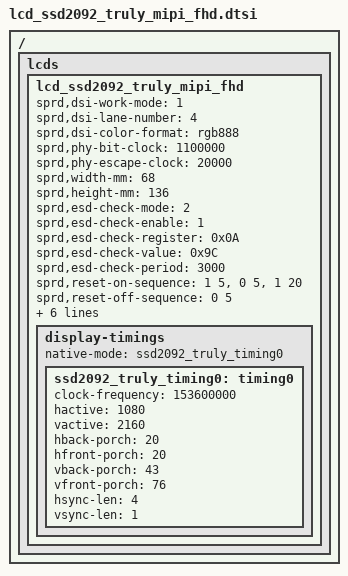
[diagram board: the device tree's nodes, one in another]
// SPDX-License-Identifier: GPL-2.0-only
/*
 * Unisoc SSD2092 Truly LCD config DTS file
 *
 * Copyright (C) 2021, Unisoc Inc.
 */
/ {
	fragment {
		target-path = "/";
		__overlay__ {
			lcds {
				lcd_ssd2092_truly_mipi_fhd: lcd_ssd2092_truly_mipi_fhd {

					sprd,dsi-work-mode = <1>; /* video burst mode*/
					sprd,dsi-lane-number = <4>;
					sprd,dsi-color-format = "rgb888";

					sprd,phy-bit-clock = <1100000>;  /* kbps */
					sprd,phy-escape-clock = <20000>; /* kHz */

					sprd,width-mm = <68>;
					sprd,height-mm = <136>;

					sprd,esd-check-mode = <2>;
					sprd,esd-check-enable = <1>;
					sprd,esd-check-register = <0x0A>;
					sprd,esd-check-value = <0x9C>;
					sprd,esd-check-period = <3000>;

					sprd,reset-on-sequence = <1 5>, <0 5>, <1 20>;
					sprd,reset-off-sequence = <0 5>;

					sprd,initial-command = [
						29 00 00 03 B5 00 00
						29 00 00 03 B3 03 96
						29 00 00 03 B4 21 FF
						29 00 00 03 E1 00 00
						29 00 00 04 E1 03 00 10
						29 00 00 03 B0 04 01
						29 00 00 03 B0 07 14
						29 00 00 03 C6 04 2D
						29 00 00 03 B9 0E 44
						29 00 00 03 C1 0C 26
						29 00 00 03 C1 08 99
						29 00 00 03 B9 23 00
						29 00 00 03 C2 04 0F
						29 00 00 03 B9 11 22
						29 00 00 03 B9 12 22
						29 00 00 03 B9 13 22
						29 00 00 03 B3 19 0B
						29 00 00 03 B0 3D C8
						29 00 00 03 B3 0F 20
						29 00 00 02 36 02
						29 00 00 03 C7 01 09
						29 00 00 03 B3 15 80
						29 00 00 03 B3 1E 02
						29 00 00 03 B3 14 C0
						29 00 00 03 B3 16 50
						29 00 00 03 B3 1C E4
						29 00 00 03 B3 28 09
						29 00 00 03 B3 24 19
						29 00 00 03 B0 12 00
						29 00 00 03 B0 13 14
						29 00 00 03 B0 1A 00
						29 00 00 03 B0 1B 14
						29 00 00 03 C1 0D 87
						29 00 00 03 C1 0E 87
						29 00 00 17 C3 00 10 2E 3E 48 5E 6B 7A 83 97 A3
							A8 A5 AC AD B5 C1 C4 4E 4F 59 5A
						29 00 00 17 C3 15 10 2E 3E 48 5E 6B 7A 83 97 A3
							A8 A5 AC AD B5 C1 C4 4E 4F 59 5A
						29 00 00 03 BB 01 8A
						29 00 00 03 BB 02 23
						29 00 00 03 BB 03 BC
						29 00 00 03 BB 04 C0
						29 00 00 03 BB 05 19
						29 00 00 03 BB 06 37
						29 00 00 03 BB 07 EE
						29 00 00 03 BB 08 DD
						29 00 00 03 BB 09 CC
						29 00 00 03 BB 0A 36
						29 00 00 03 BB 0B 70
						29 00 00 03 BB 0C 00
						29 00 00 03 BB 0D 8A
						29 00 00 03 BB 0E 23
						29 00 00 03 BB 0F BC
						29 00 00 03 BB 10 C0
						29 00 00 03 BB 11 18
						29 00 00 03 BB 12 A7
						29 00 00 03 BB 13 EE
						29 00 00 03 BB 14 DD
						29 00 00 03 BB 15 CC
						29 00 00 03 BB 16 36
						29 00 00 03 BB 17 70
						29 00 00 03 BB 18 00
						29 00 00 03 BB 31 01
						29 00 00 03 BD 00 F0
						29 00 00 03 BD 01 F0
						29 00 00 03 BD 02 F0
						29 00 00 03 BD 03 F0
						29 00 00 03 BD 1A 02
						29 00 00 03 BD 1B 24
						29 00 00 03 BD 1D 01
						29 00 00 03 BD 1E 01
						29 00 00 03 BD 21 00
						29 00 00 03 BD 1F 79
						29 00 00 03 BD 20 14
						29 00 00 03 BD 22 89
						29 00 00 03 BD 23 13
						29 00 00 03 BD 24 35
						29 00 00 03 BD 26 01
						29 00 00 03 BD 27 01
						29 00 00 03 BD 2A 00
						29 00 00 03 BD 28 79
						29 00 00 03 BD 29 14
						29 00 00 03 BD 2B 89
						29 00 00 03 BD 2C 33
						29 00 00 03 BD 2D 33
						29 00 00 03 BD 2E 11
						29 00 00 03 BD 2F 11
						29 00 00 03 BD 31 22
						29 00 00 03 BD 32 01
						29 00 00 03 BD 33 04
						29 00 00 03 BD 34 11
						29 00 00 03 BD 35 11
						29 00 00 03 BD 37 22
						29 00 00 03 BD 38 01
						29 00 00 03 BD 39 04
						29 00 00 03 BD 3A 1E
						29 00 00 03 BD 3B 1E
						29 00 00 03 BD 3C 1E
						29 00 00 03 BD 3D 1E
						29 00 00 03 BD 40 AA
						29 00 00 03 BD 42 1E
						29 00 00 03 BD 43 1E
						29 00 00 03 BD 44 1E
						29 00 00 03 BD 45 1E
						29 00 00 03 BD 48 AA
						29 00 00 03 BA 02 05
						29 00 00 03 BA 03 01
						29 00 00 03 BC 1E 71
						29 00 00 03 BC 24 83
						29 00 00 03 B8 03 A9
						29 00 00 03 BA 15 41
						29 00 00 03 BB 19 8A
						29 00 00 03 BB 1A 32
						29 00 00 03 BB 1B BC
						29 00 00 03 BB 1C C2
						29 00 00 03 BB 1D 39
						29 00 00 03 BB 1E 37
						29 00 00 03 BB 1F EE
						29 00 00 03 BB 20 DD
						29 00 00 03 BB 21 CC
						29 00 00 03 BB 22 36
						29 00 00 03 BB 23 70
						29 00 00 03 BB 24 00
						29 00 00 03 BB 25 8A
						29 00 00 03 BB 26 32
						29 00 00 03 BB 27 BC
						29 00 00 03 BB 28 C2
						29 00 00 03 BB 29 38
						29 00 00 03 BB 2A A7
						29 00 00 03 BB 2B EE
						29 00 00 03 BB 2C DD
						29 00 00 03 BB 2D CC
						29 00 00 03 BB 2E 36
						29 00 00 03 BB 2F 70
						29 00 00 03 BB 30 00
						29 00 00 03 B8 15 A2
						29 00 00 03 B0 39 00
						29 00 00 04 C6 00 03 40
						29 00 00 03 B3 18 00
						29 00 00 03 BA 17 28
						29 00 00 03 BA 23 15
						29 00 00 03 B0 06 2C
						29 00 00 03 BA 17 28
						29 00 00 03 BA 23 15
						29 00 00 03 BA 16 00
						29 00 00 04 BA 28 02 02
						29 00 00 03 BA 0F 8C
						29 00 00 03 BA 10 0C
						29 00 00 03 BA 11 23
						29 00 00 05 BA 12 9D 9D 9D
						29 00 00 03 BA 25 22
						29 00 00 04 BA 0D 40 02
						29 00 00 03 BA 2F 8C
						29 00 00 03 C2 04 00
						29 00 00 03 C2 05 C0
						29 00 00 0b B9 11 00 00 00 00 00 00 00 00 00
						29 00 00 03 BA 15 33
						29 00 00 06 B9 00 5F 5F 61 0A
						29 00 00 03 BD 08 07
						29 00 00 03 BD 09 07
						29 00 00 03 BC 03 00
						29 00 00 03 BC 04 00
						29 00 00 03 BC 05 00
						29 00 00 03 BC 07 10
						29 00 00 03 BC 08 10
						29 00 00 03 BC 09 10
						29 00 00 03 B9 11 00
						29 00 00 03 B9 12 00
						29 00 00 03 B9 13 00
						29 00 00 03 B9 1D 00
						29 00 00 03 B9 1E 00
						29 00 00 03 B9 1F 00
						29 00 00 03 C2 00 07
						29 00 00 03 C1 0B 1F
						29 00 00 03 B1 05 2F
						29 00 00 02 35 00
						29 00 00 04 B0 01 08 70
						29 00 00 03 B9 25 A0
						29 00 00 03 BA 2F CC
						29 00 00 03 C1 02 B0
						29 00 00 03 B3 1C C4
						29 00 00 03 B3 1D 80
						29 00 00 04 BD 11 02 22
						29 00 00 02 36 0A
						39 00 00 02 51 FF
						39 00 00 02 53 2C
						39 00 00 02 55 00
						05 14 00 01 11
						05 64 00 01 29
						];

					sprd,sleep-in-command = [
						13 0A 00 01 28
						13 78 00 01 10
						];
					sprd,sleep-out-command = [
						13 78 00 01 11
						13 32 00 01 29
						];

					display-timings {
						native-mode = <&ssd2092_truly_timing0>;

						ssd2092_truly_timing0: timing0 {
							clock-frequency = <153600000>;
							hactive = <1080>;
							vactive = <2160>;
							hback-porch = <20>;
							hfront-porch = <20>;
							vback-porch = <43>;
							vfront-porch = <76>;
							hsync-len = <4>;
							vsync-len = <1>;
						};
					};
				};
			};
		};
	};
};
